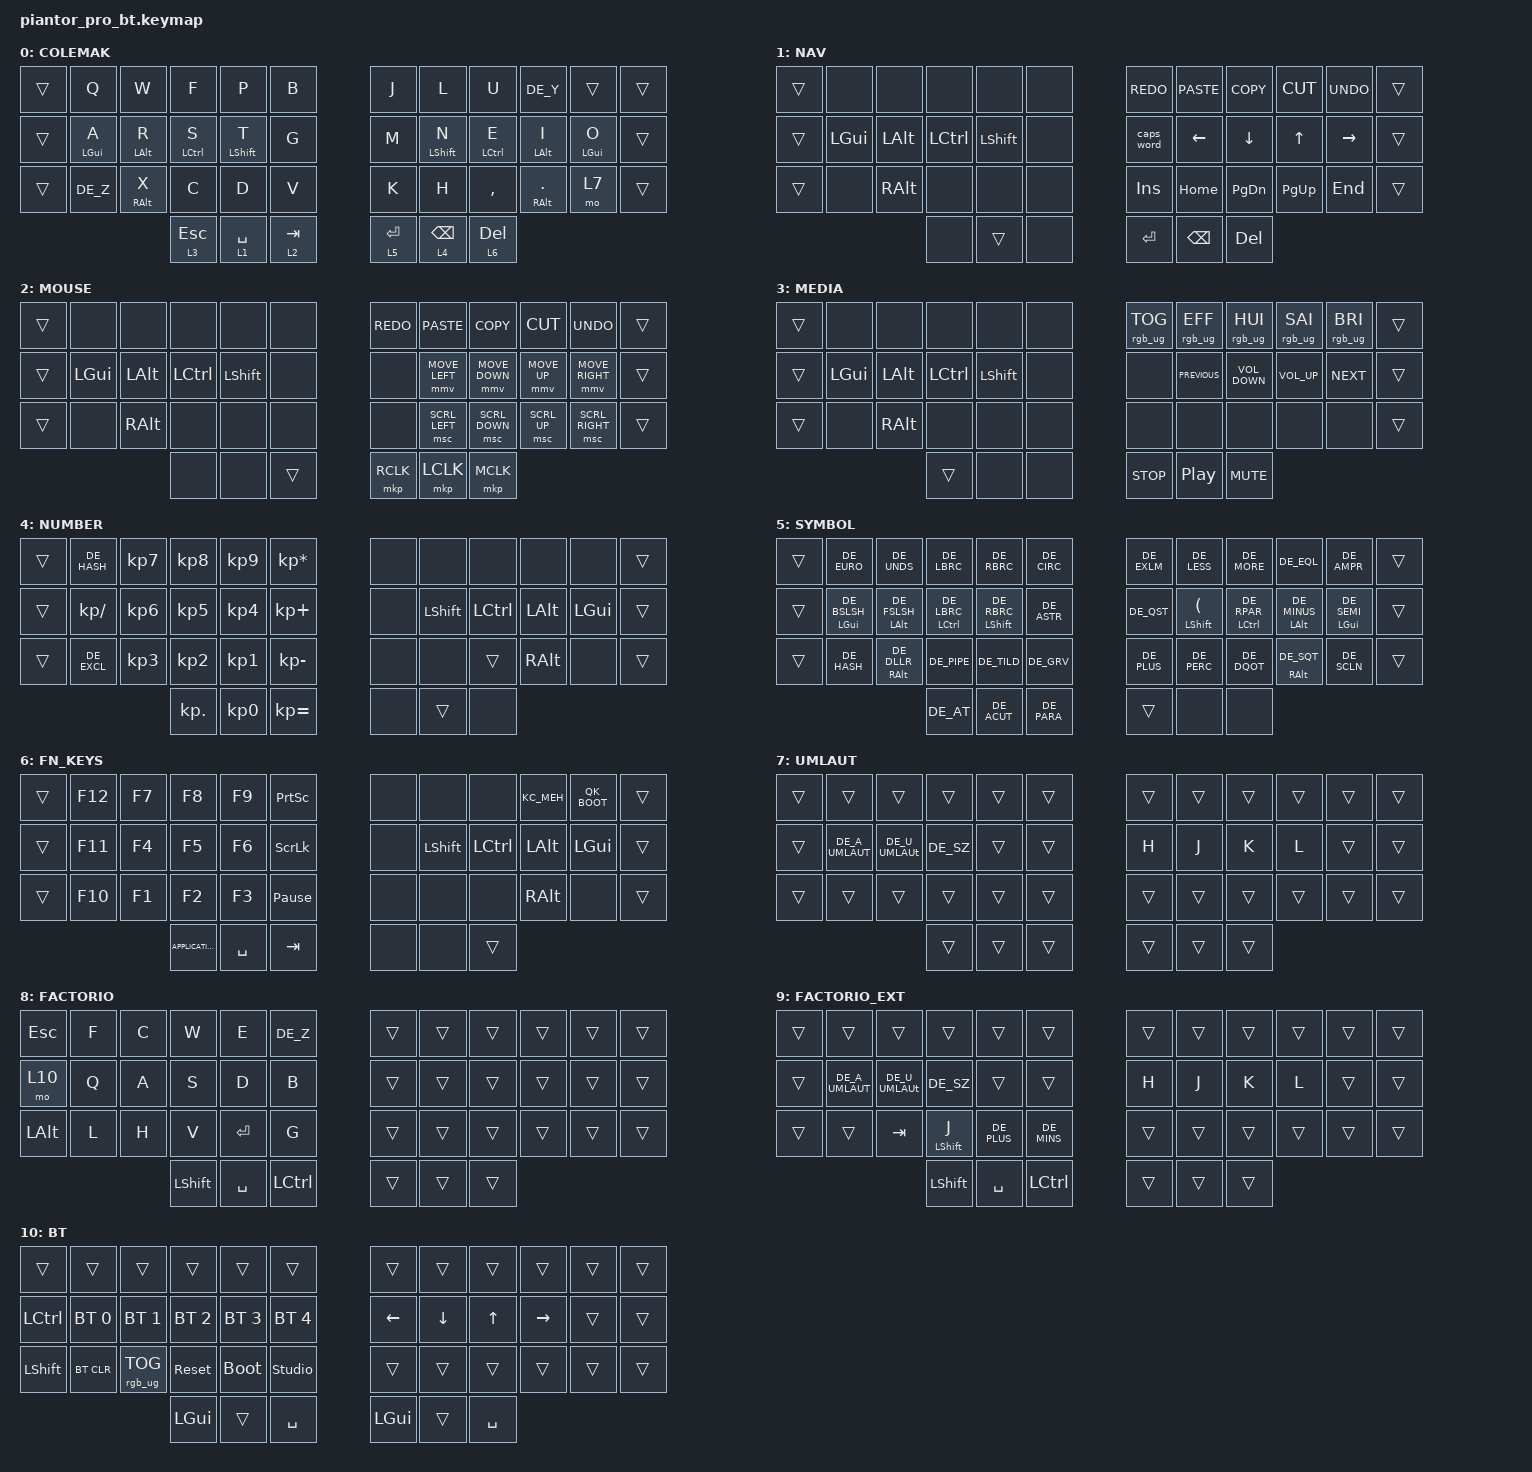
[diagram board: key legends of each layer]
/*
 * Copyright (c) 2020 The ZMK Contributors
 *
 * SPDX-License-Identifier: MIT
 */

#include <behaviors.dtsi>
#include <dt-bindings/zmk/keys.h>
#include <dt-bindings/zmk/bt.h>
#include <dt-bindings/zmk/rgb.h>

#include "keys_de.h"
// TODO:
//  - bootloader keys
//  - BT keys
//  - caps-word
//  - configure mouse-movement correctly --> https://zmk.dev/docs/keymaps/behaviors/mouse-emulation

/ {
    chosen {
        zmk,physical-layout = &default_layout;
    };
};

/ {
    keymap {
        compatible = "zmk,keymap";

        default_layer {
            display-name = "COLEMAK";
            bindings = <
                &trans &kp Q      &kp W      &kp F       &kp P        &kp B     /**/ &kp J      &kp L          &kp U          &kp DE_Y     &trans          &trans
                &trans &mt LGUI A &mt LALT R &mt LCTRL S &mt LSHFT T  &kp G     /**/ &kp M      &mt LSHFT N    &mt LCTRL E    &mt LALT I   &mt LGUI O      &trans
                &trans &kp DE_Z   &mt RALT X &kp C       &kp D        &kp V     /**/ &kp K      &kp H          &kp COMMA      &mt RALT DOT &mo 7           &trans
                                             &lt 3 ESC   &lt 1 SPACE  &lt 2 TAB /**/ &lt 5 RET  &lt 4 BSPC     &lt 6 DEL
            >;
        };

        navigation_layer {
            display-name = "NAV";
            bindings = <
                // TODO: should i rather use C_REDO etc?
                &trans &none     &none       &none       &none        &none     /**/ &kp K_REDO &kp K_PASTE    &kp K_COPY     &kp K_CUT    &kp K_UNDO      &trans
                &trans &kp LGUI  &kp LALT    &kp LCTRL   &kp LSHFT    &none     /**/ &caps_word &kp LEFT       &kp DOWN       &kp UP       &kp RIGHT       &trans
                &trans &none     &kp RALT    &none       &none        &none     /**/ &kp INSERT &kp HOME       &kp PG_DN      &kp PG_UP    &kp END         &trans
                                             &none       &trans       &none     /**/ &kp RET    &kp BSPC       &kp DEL
            >;
        };
        // not sure if this is still needed... used veeeeery infrequently
        mouse_layer {
            display-name = "MOUSE";
            bindings = <
                &trans &none     &none       &none       &none        &none     /**/ &kp K_REDO &kp  K_PASTE   &kp  K_COPY    &kp  K_CUT   &kp  K_UNDO     &trans
                &trans &kp LGUI  &kp LALT    &kp LCTRL   &kp LSHFT    &none     /**/ &none      &mmv MOVE_LEFT &mmv MOVE_DOWN &mmv MOVE_UP &mmv MOVE_RIGHT &trans
                &trans &none     &kp RALT    &none       &none        &none     /**/ &none      &msc SCRL_LEFT &msc SCRL_DOWN &msc SCRL_UP &msc SCRL_RIGHT &trans
                                             &none       &none        &trans    /**/ &mkp RCLK  &mkp LCLK      &mkp MCLK
            >;
        };

        media_layer {
            display-name = "MEDIA";
            bindings = <
                &trans &none     &none       &none       &none        &none     /**/ &rgb_ug RGB_TOG &rgb_ug RGB_EFF   &rgb_ug RGB_HUI   &rgb_ug RGB_SAI &rgb_ug RGB_BRI &trans
                &trans &kp LGUI  &kp LALT    &kp LCTRL   &kp LSHFT    &none     /**/ &none           &kp C_PREVIOUS    &kp C_VOLUME_DOWN &kp C_VOLUME_UP &kp C_NEXT      &trans
                &trans &none     &kp RALT    &none       &none        &none     /**/ &none           &none             &none             &none           &none      &trans
                                             &trans      &none        &none     /**/ &kp C_STOP      &kp C_PLAY_PAUSE  &kp C_MUTE
            >;
        };

        numbers_layer {
            display-name = "NUMBER";
            bindings = <
                &trans &kp DE_HASH   &kp KP_N7  &kp KP_N8  &kp KP_N9  &kp KP_MULTIPLY  /**/ &none &none     &none     &none    &none    &trans
                &trans &kp KP_DIVIDE &kp KP_N6  &kp KP_N5  &kp KP_N4  &kp KP_PLUS      /**/ &none &kp LSHFT &kp LCTRL &kp LALT &kp LGUI &trans
                &trans &kp DE_EXCL   &kp KP_N3  &kp KP_N2  &kp KP_N1  &kp KP_MINUS     /**/ &none &none     &trans    &kp RALT &none    &trans
                                                &kp KP_DOT &kp KP_N0  &kp KP_EQUAL     /**/ &none &trans    &none
            >;
        };

        symbols_layer {
            display-name = "SYMBOL";
            bindings = <
                // XXX: unverified keymaps just hoped for the best after converting
                &trans &kp DE_EURO       &kp DE_UNDS       &kp DE_LBRC       &kp DE_RBRC       &kp DE_CIRC /**/ &kp DE_EXLM &kp DE_LESS    &kp DE_MORE &kp DE_EQL &kp DE_AMPR &trans
                &trans &mt LGUI DE_BSLSH &mt LALT DE_FSLSH &mt LCTRL DE_LBRC &mt LSHFT DE_RBRC &kp DE_ASTR /**/ &kp DE_QST  &mt LSHFT LPAR &mt LCTRL DE_RPAR &mt LALT DE_MINUS &mt LGUI DE_SEMI &trans
                &trans &kp DE_HASH &mt RALT DE_DLLR &kp DE_PIPE &kp DE_TILD &kp DE_GRV /**/ DE_PLUS &kp DE_PERC &kp DE_DQOT &mt RALT DE_SQT &kp DE_SCLN &trans
                                                   &kp DE_AT &kp DE_ACUT &kp DE_PARA /**/ &trans &none &none
            >;
        };

        function_layer {
            display-name = "FN_KEYS";
            bindings = <
                &trans &kp F12 &kp F7 &kp F8 &kp F9 &kp PRINTSCREEN /**/ &none &none     &none [[KC_MEH]] [[QK_BOOT]] &trans
                &trans &kp F11 &kp F4 &kp F5 &kp F6 &kp SCROLLLOCK  /**/ &none &kp LSHFT &kp LCTRL &kp LALT &kp LGUI &trans
                &trans &kp F10 &kp F1 &kp F2 &kp F3 &kp PAUSE_BREAK /**/ &none &none     &none     &kp RALT &none    &trans
                                &kp K_APPLICATION &kp SPACE &kp TAB /**/ &none &none     &trans
            >;
        };

        umlaute_layer {
            display-name = "UMLAUT"; // quick access to umlauts and vim hjkl binding
            bindings = <
                &trans &trans &trans &trans &trans &trans /**/ &trans &trans &trans &trans &trans &trans
                &trans &kp DE_A_UMLAUT &kp DE_U_UMLAUt &kp DE_SZ &trans /**/ &trans &kp H &kp J &kp K &kp L &trans &trans
                &trans &trans &trans &trans &trans &trans /**/ &trans &trans &trans &trans &trans &trans
                                     &trans &trans &trans /**/ &trans &trans &trans
            >;
        };
        factorio_case {
            // TODO: maybe those layers need to be revised!
            display-name = "FACTORIO";
            bindings = <
                &kp ESC  &kp F &kp C &kp W &kp E   &kp DE_Z /**/ &trans &trans &trans &trans &trans &trans
                &mo 10   &kp Q &kp A &kp S &kp D   &kp B    /**/ &trans &trans &trans &trans &trans &trans
                &kp LALT &kp L &kp H &kp V &kp RET &kp G    /**/ &trans &trans &trans &trans &trans &trans
                              &kp LSHFT &kp SPACE &kp LCTRL /**/ &trans &trans &trans
            >;
        };
        factorio_ext {
            display-name = "FACTORIO_EXT";
            bindings = <
                &trans &trans &trans &trans &trans &trans /**/ &trans &trans &trans &trans &trans &trans
                &trans &kp DE_A_UMLAUT &kp DE_U_UMLAUt &kp DE_SZ &trans /**/ &trans &kp H &kp J &kp K &kp L &trans &trans
                &trans &trans &kp TAB &mt LEFT_SHIFT J &kp DE_PLUS &kp DE_MINS /**/ &trans &trans &trans &trans &trans &trans
                                    &kp LSHFT &kp SPACE &kp LCTRL /**/ &trans &trans &trans
            >;
        };
        bt_config {
        // just copied from default, need to be adopted
            display-name = "BT";
            bindings = <
                &trans &trans &trans &trans &trans &trans  &trans &trans &trans &trans &trans &trans
                &kp LCTRL &bt BT_SEL 0 &bt BT_SEL 1    &bt BT_SEL 2 &bt BT_SEL 3 &bt BT_SEL 4   &kp LEFT &kp DOWN &kp UP &kp RIGHT &trans &trans
                &kp LSHFT &bt BT_CLR   &rgb_ug RGB_TOG &sys_reset   &bootloader  &studio_unlock &trans   &trans   &trans &trans    &trans &trans
                                                       &kp LGUI     &trans       &kp SPACE      &kp LGUI &trans   &kp SPACE
            >;
        };
    };
};
